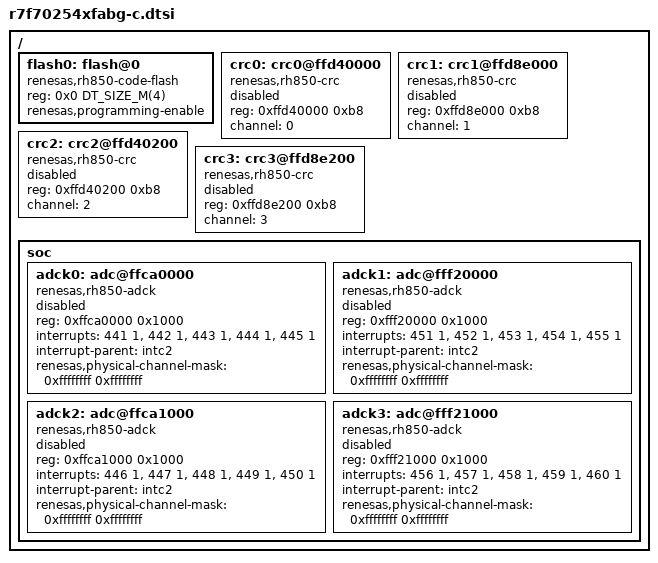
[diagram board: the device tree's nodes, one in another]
/*
 * Copyright (c) 2026 Renesas Electronics Corporation
 *
 * SPDX-License-Identifier: Apache-2.0
 */

#include <rh850/renesas/rh850u2b/r7f70254x.dtsi>

/ {
	flash0: flash@0 {
		compatible = "renesas,rh850-code-flash";
		reg = <0x0 DT_SIZE_M(4)>;
		renesas,programming-enable;
	};

	crc0: crc0@ffd40000 {
		compatible = "renesas,rh850-crc";
		reg = <0xffd40000 0xb8>;
		channel = <0>;
		status = "disabled";
	};

	crc1: crc1@ffd8e000 {
		compatible = "renesas,rh850-crc";
		reg = <0xffd8e000 0xb8>;
		channel = <1>;
		status = "disabled";
	};

	crc2: crc2@ffd40200 {
		compatible = "renesas,rh850-crc";
		reg = <0xffd40200 0xb8>;
		channel = <2>;
		status = "disabled";
	};

	crc3: crc3@ffd8e200 {
		compatible = "renesas,rh850-crc";
		reg = <0xffd8e200 0xb8>;
		channel = <3>;
		status = "disabled";
	};

	soc {
		adck0: adc@ffca0000 {
			compatible = "renesas,rh850-adck";
			reg = <0xffca0000 0x1000>;
			interrupts = <441 1>, <442 1>, <443 1>, <444 1>, <445 1>;
			interrupt-names = "sg0", "sg1", "sg2", "sg3", "sg4";
			interrupt-parent = <&intc2>;
			#io-channel-cells = <1>;
			#address-cells = <1>;
			#size-cells = <0>;
			renesas,physical-channel-mask = <0xffffffff 0xffffffff>;
			status = "disabled";
		};

		adck1: adc@fff20000 {
			compatible = "renesas,rh850-adck";
			reg = <0xfff20000 0x1000>;
			interrupts = <451 1>, <452 1>, <453 1>, <454 1>, <455 1>;
			interrupt-names = "sg0", "sg1", "sg2", "sg3", "sg4";
			interrupt-parent = <&intc2>;
			#io-channel-cells = <1>;
			#address-cells = <1>;
			#size-cells = <0>;
			renesas,physical-channel-mask = <0xffffffff 0xffffffff>;
			status = "disabled";
		};

		adck2: adc@ffca1000 {
			compatible = "renesas,rh850-adck";
			reg = <0xffca1000 0x1000>;
			interrupts = <446 1>, <447 1>, <448 1>, <449 1>, <450 1>;
			interrupt-names = "sg0", "sg1", "sg2", "sg3", "sg4";
			interrupt-parent = <&intc2>;
			#io-channel-cells = <1>;
			#address-cells = <1>;
			#size-cells = <0>;
			renesas,physical-channel-mask = <0xffffffff 0xffffffff>;
			status = "disabled";
		};

		adck3: adc@fff21000 {
			compatible = "renesas,rh850-adck";
			reg = <0xfff21000 0x1000>;
			interrupts = <456 1>, <457 1>, <458 1>, <459 1>, <460 1>;
			interrupt-names = "sg0", "sg1", "sg2", "sg3", "sg4";
			interrupt-parent = <&intc2>;
			#io-channel-cells = <1>;
			#address-cells = <1>;
			#size-cells = <0>;
			renesas,physical-channel-mask = <0xffffffff 0xffffffff>;
			status = "disabled";
		};
	};
};
